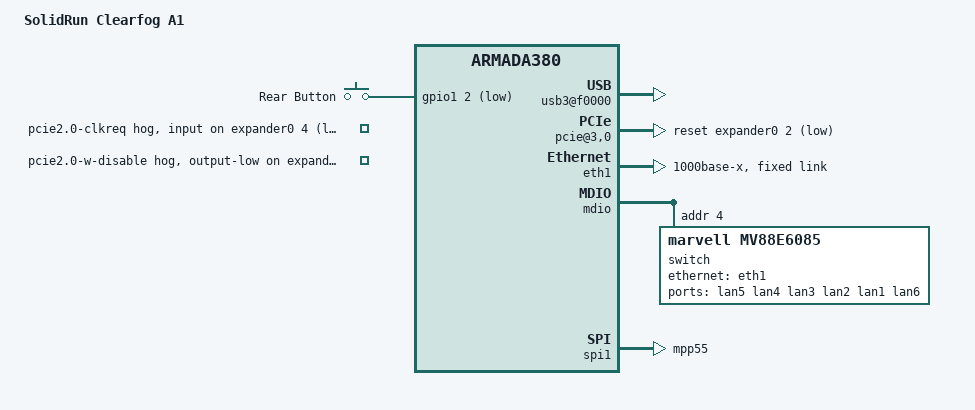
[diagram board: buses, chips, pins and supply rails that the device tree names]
/dts-v1/;
#include "armada-388-clearfog.dtsi"
/ {
	model = "SolidRun Clearfog A1";
	compatible = "solidrun,clearfog-a1", "marvell,armada388",
		"marvell,armada385", "marvell,armada380";
	soc {
		internal-regs {
			usb3@f0000 {
				status = "okay";
			};
		};
		pcie {
			pcie@3,0 {
				reset-gpios = <&expander0 2 GPIO_ACTIVE_LOW>;
				status = "okay";
			};
		};
	};
	gpio-keys {
		compatible = "gpio-keys";
		pinctrl-0 = <&rear_button_pins>;
		pinctrl-names = "default";
		button-0 {
			label = "Rear Button";
			gpios = <&gpio1 2 GPIO_ACTIVE_LOW>;
			linux,can-disable;
			linux,code = <BTN_0>;
		};
	};
};
&eth1 {
	phy-mode = "1000base-x";
	fixed-link {
		speed = <1000>;
		full-duplex;
	};
};
&expander0 {
	pcie2-0-clkreq-hog {
		gpio-hog;
		gpios = <4 GPIO_ACTIVE_LOW>;
		input;
		line-name = "pcie2.0-clkreq";
	};
	pcie2-0-w-disable-hog {
		gpio-hog;
		gpios = <7 GPIO_ACTIVE_LOW>;
		output-low;
		line-name = "pcie2.0-w-disable";
	};
};
&mdio {
	status = "okay";
	switch@4 {
		compatible = "marvell,mv88e6085";
		#address-cells = <1>;
		#size-cells = <0>;
		reg = <4>;
		pinctrl-0 = <&clearfog_dsa0_clk_pins &clearfog_dsa0_pins>;
		pinctrl-names = "default";
		ports {
			#address-cells = <1>;
			#size-cells = <0>;
			port@0 {
				reg = <0>;
				label = "lan5";
			};
			port@1 {
				reg = <1>;
				label = "lan4";
			};
			port@2 {
				reg = <2>;
				label = "lan3";
			};
			port@3 {
				reg = <3>;
				label = "lan2";
			};
			port@4 {
				reg = <4>;
				label = "lan1";
			};
			port@5 {
				reg = <5>;
				ethernet = <&eth1>;
				phy-mode = "1000base-x";
				fixed-link {
					speed = <1000>;
					full-duplex;
				};
			};
			port@6 {
				reg = <6>;
				label = "lan6";
				phy-mode = "rgmii-id";
				fixed-link {
					speed = <1000>;
					full-duplex;
				};
			};
		};
	};
};
&pinctrl {
	clearfog_dsa0_clk_pins: clearfog-dsa0-clk-pins {
		marvell,pins = "mpp46";
		marvell,function = "ref";
	};
	clearfog_dsa0_pins: clearfog-dsa0-pins {
		marvell,pins = "mpp23", "mpp41";
		marvell,function = "gpio";
	};
	clearfog_spi1_cs_pins: spi1-cs-pins {
		marvell,pins = "mpp55";
		marvell,function = "spi1";
	};
	rear_button_pins: rear-button-pins {
		marvell,pins = "mpp34";
		marvell,function = "gpio";
	};
};
&spi1 {
	pinctrl-0 = <&spi1_pins &clearfog_spi1_cs_pins &mikro_spi_pins>;
};
